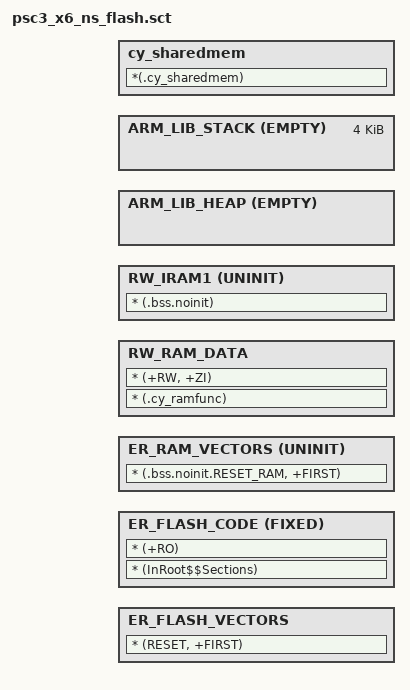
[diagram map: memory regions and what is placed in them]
#! armclang -E --target=arm-arm-none-eabi -x c -mcpu=cortex-m33
; The first line specifies a preprocessor command that the linker invokes
; to pass a scatter file through a C preprocessor.

;*******************************************************************************
;* \file psc3xxf_ns_flash.sct
;* \version 1.000
;*
;* Linker file for the ARMCC.
;*
;* The main purpose of the linker script is to describe how the sections in the
;* input files should be mapped into the output file, and to control the memory
;* layout of the output file.
;*
;* \note The entry point location is fixed and starts at 0x02010000. The valid
;* application image should be placed there.
;*
;* \note The linker files included with the PDL template projects must be generic
;* and handle all common use cases. Your project may not use every section
;* defined in the linker files. In that case you may see warnings during the
;* build process. In your project, you can simply comment out or remove the
;* relevant code in the linker file.
;*******************************************************************************
;* \copyright
;* Copyright (c) 2026, Infineon Technologies AG, or an affiliate of Infineon
;* Technologies.
;* SPDX-License-Identifier: Apache-2.0
;*
;* Licensed under the Apache License, Version 2.0 (the "License");
;* you may not use this file except in compliance with the License.
;* You may obtain a copy of the License at
;*
;*     http://www.apache.org/licenses/LICENSE-2.0
;*
;* Unless required by applicable law or agreed to in writing, software
;* distributed under the License is distributed on an "AS IS" BASIS,
;* WITHOUT WARRANTIES OR CONDITIONS OF ANY KIND, either express or implied.
;* See the License for the specific language governing permissions and
;* limitations under the License.
;******************************************************************************/

; Include the device memory definitions generated by the Device Configurator
#include "../config/GeneratedSource/cymem_armlink_CM33_0.sct"

; The size of the stack section at the end of CM4 SRAM
#define STACK_SIZE                 0x1000  /* 4K for stack */

; MCUBoot header size. Default is 0 (no MCUBoot header).
#ifndef MCUBOOT_HEADER_SIZE
#define MCUBOOT_HEADER_SIZE        0x0
#endif


; Cortex-M33 application flash area
LR_IROM1 (CYMEM_CM33_0_m33ns_nvm_C_START + MCUBOOT_HEADER_SIZE) (CYMEM_CM33_0_m33ns_nvm_SIZE - MCUBOOT_HEADER_SIZE)
{
    ER_FLASH_VECTORS +0
    {
        * (RESET, +FIRST)
    }

    ER_FLASH_CODE +0 FIXED
    {
        * (InRoot$$Sections)
        * (+RO)
    }

    ER_RAM_VECTORS CYMEM_CM33_0_m33ns_data_START UNINIT
    {
        * (.bss.noinit.RESET_RAM, +FIRST)
    }

    RW_RAM_DATA +0
    {
        * (.cy_ramfunc)
        * (+RW, +ZI)
    }

    ; Place variables in the section that should not be initialized during the
    ; device startup.
    RW_IRAM1 +0 UNINIT
    {
        * (.bss.noinit)
    }

    ; Application heap area (HEAP)
    ARM_LIB_HEAP  +0 EMPTY ((CYMEM_CM33_0_m33ns_data_START+CYMEM_CM33_0_m33ns_data_SIZE)-AlignExpr(ImageLimit(RW_IRAM1), 8)-STACK_SIZE)
    {
    }

    ; Stack region growing down
    ARM_LIB_STACK (CYMEM_CM33_0_m33ns_data_START+CYMEM_CM33_0_m33ns_data_SIZE) EMPTY -STACK_SIZE
    {
    }

    cy_sharedmem CYMEM_CM33_0_m33ns_shm_data_START CYMEM_CM33_0_m33ns_shm_data_SIZE
    {
        *(.cy_sharedmem)
    }
}

/* [] END OF FILE */
